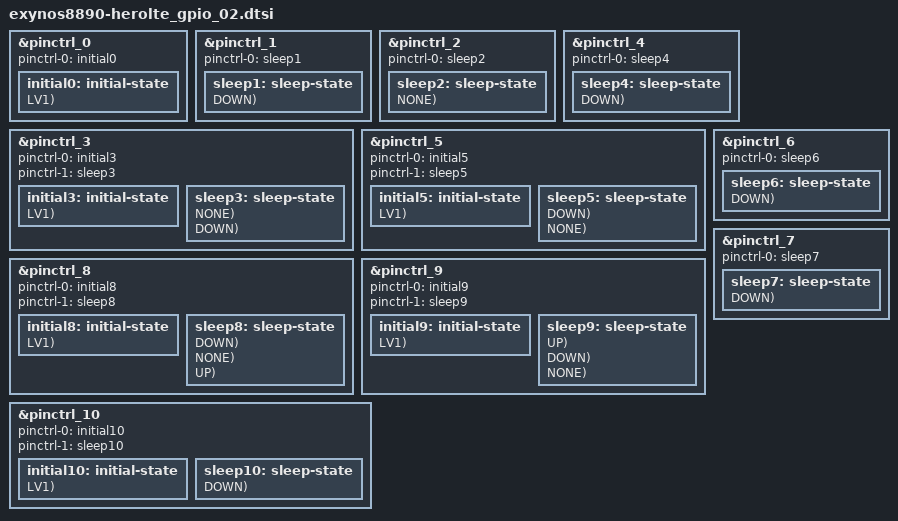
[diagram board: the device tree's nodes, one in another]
/*
 * Copyright (c) 2015 Samsung Electronics Co., Ltd.
 *		http://www.samsung.com
 *
 * This program is free software; you can redistribute it and/or modify
 * it under the terms of the GNU General Public License version 2 as
 * published by the Free Software Foundation.
*/

// Support LUCKY LTE HW REV0.7 (b1011)

#include "exynos_gpio_config_macros.dtsi"

// gpa: pinctrl_0
&pinctrl_0 {
	pinctrl-names = "default";
	pinctrl-0 = <&initial0>;
	initial0: initial-state {
		PIN_IN(gpa3-7, NONE, LV1);	/* 2ndCG_nIRQ */
	};
};

// gph0: do not add init setting for NC pins!!!
&pinctrl_1 {
	pinctrl-names = "sleep";
	pinctrl-0 = <&sleep1>;
	sleep1: sleep-state {
		PIN_SLP(gph0-0, INPUT, DOWN);	/* MM_I2S_CLK */
		PIN_SLP(gph0-1, INPUT, DOWN);	/* NC */
		PIN_SLP(gph0-2, INPUT, DOWN);	/* MM_I2S_SYNC */
		PIN_SLP(gph0-3, INPUT, DOWN);	/* MM_I2S_D_IN */
		PIN_SLP(gph0-4, INPUT, DOWN);	/* MM_I2S_D_OUT */
		PIN_SLP(gph0-5, INPUT, DOWN);	/* NC */
		PIN_SLP(gph0-6, INPUT, DOWN);	/* NC */
	};
};

// etc0
&pinctrl_2 {
	pinctrl-names = "sleep";
	pinctrl-0 = <&sleep2>;
	sleep2: sleep-state {
		PIN_SLP(etc0-0, PREV, NONE);	/* PMIC_SDA_1P8 */
		PIN_SLP(etc0-1, PREV, NONE);	/* PMIC_SCL_1P8 */
	};
};

// gpf3
&pinctrl_3 {
	pinctrl-names = "default","sleep";
	pinctrl-0 = <&initial3>;
	pinctrl-1 = <&sleep3>;
	initial3: initial-state {
		PIN_IN(gpf3-4, DOWN, LV1);	/* NC */
	};
	sleep3: sleep-state {
		PIN_SLP(gpf3-0, OUT0, NONE);	/* BTP_SPI_CLK */
		PIN_SLP(gpf3-1, OUT0, NONE);	/* BTP_SPI_CS_N */
		PIN_SLP(gpf3-2, INPUT, DOWN);	/* BTP_SPI_MISO */
		PIN_SLP(gpf3-3, OUT0, NONE);	/* BTP_SPI_MOSI */
		PIN_SLP(gpf3-4, INPUT, DOWN);	/* NC */
	};
};


// gpf2
&pinctrl_4 {
	pinctrl-names = "sleep";
	pinctrl-0 = <&sleep4>;
	sleep4: sleep-state {
		PIN_SLP(gpf2-0, INPUT, DOWN);	/* ESE_SPI_CLK */
		PIN_SLP(gpf2-1, INPUT, DOWN);	/* ESE_SPI_CS_N */
		PIN_SLP(gpf2-2, INPUT, DOWN);	/* ESE_SPI_MISO */
		PIN_SLP(gpf2-3, INPUT, DOWN);	/* ESE_SPI_MOSI */
	};
};

// gpi1, gpi2
&pinctrl_5 {
	pinctrl-names = "default","sleep";
	pinctrl-0 = <&initial5>;
	pinctrl-1 = <&sleep5>;
	initial5: initial-state {
		PIN_IN(gpi1-1, DOWN, LV1);	/* NC */

		PIN_IN(gpi2-5, DOWN, LV1);/* FG_ERR */
	};
	sleep5: sleep-state {
		PIN_SLP(gpi1-0, PREV, DOWN);	/* MST_PWR_EN */
		PIN_SLP(gpi1-1, INPUT, DOWN);	/* NC */
		PIN_SLP(gpi1-2, PREV, NONE);	/* WPC_EN */
		PIN_SLP(gpi1-3, PREV, NONE);	/* BTP_RST_N */

		PIN_SLP(gpi2-0, PREV, NONE);	/* DISP_RST_N */
		PIN_SLP(gpi2-1, INPUT, DOWN);	/* DISP_DET */
		PIN_SLP(gpi2-2, INPUT, DOWN);	/* DS_DET */
		PIN_SLP(gpi2-3, PREV, NONE);	/* BT_WAKE */
		PIN_SLP(gpi2-4, INPUT, DOWN);	/* IFC_SENSE_INT_AP */
		PIN_SLP(gpi2-5, INPUT, DOWN);	/* FG_ERR */
		PIN_SLP(gpi2-6, INPUT, NONE);	/* SUB_PMIC_IRQ_N */
		PIN_SLP(gpi2-7, PREV, NONE);	/* NFC_EN */
	};
};

// gpj0
&pinctrl_6 {
	pinctrl-names = "sleep";
	pinctrl-0 = <&sleep6>;
	sleep6: sleep-state {
		PIN_SLP(gpj0-2, INPUT, DOWN);	/* NC */
	};
};

// gpf0
&pinctrl_7 {
	pinctrl-names = "sleep";
	pinctrl-0= <&sleep7>;
	sleep7: sleep-state {
		PIN_SLP(gpf0-0, PREV, DOWN);	/* MST_EN */
		PIN_SLP(gpf0-1, PREV, DOWN);	/* MST_DATA_A */
		PIN_SLP(gpf0-2, INPUT, DOWN);	/* MST_DATA_B (not use yet) */
	};
};

// gpi0, gpd0~gpd3, gpb0~gpb2, gpc0~gpc3, gpk0, etc1
&pinctrl_8 {
	pinctrl-names = "default","sleep";
	pinctrl-0 = <&initial8>;
	pinctrl-1 = <&sleep8>;
	initial8: initial-state {
		PIN_IN(gpi0-0, DOWN, LV1);	/* NC */
		PIN_IN(gpi0-2, DOWN, LV1);	/* NC */
		PIN_IN(gpi0-3, DOWN, LV1);	/* NC */

		PIN_IN(gpd0-7, DOWN, LV1);	/* NC */

		PIN_IN(gpb0-2, DOWN, LV1);	/* NC */

		PIN_IN(gpb1-0, DOWN, LV1);	/* NC */

		PIN_IN(gpk0-3, DOWN, LV1);	/* NC */
	};
	sleep8: sleep-state {
		PIN_SLP(gpi0-0, INPUT, DOWN);	/* NC */
		PIN_SLP(gpi0-1, INPUT, DOWN);	/* BUCK11_EN */
		PIN_SLP(gpi0-2, INPUT, DOWN);	/* NC */
		PIN_SLP(gpi0-3, INPUT, DOWN);	/* NC */
		PIN_SLP(gpi0-4, PREV, NONE);	/* UFS_RST_N */
		PIN_SLP(gpi0-5, PREV, NONE);	/* UFS_REFCLK */

		PIN_SLP(gpd0-0, INPUT, UP);	/* 2MIC_UART_RXD */
		PIN_SLP(gpd0-1, PREV, NONE);	/* 2MIC_URAT_TXD */
		PIN_SLP(gpd0-2, PREV, NONE);	/* 2MIC_RST */
		PIN_SLP(gpd0-3, INPUT, DOWN);	/* 2MIC_INT */
		PIN_SLP(gpd0-4, PREV, NONE);	/* DISP_EN_1P6 */
		PIN_SLP(gpd0-5, OUT0, NONE);	/* VIB_PWN */
		PIN_SLP(gpd0-6, OUT1, NONE);    /* PMIC_WRST_IN */
		PIN_SLP(gpd0-7, INPUT, DOWN);	/* NC */

		PIN_SLP(gpd1-0, INPUT, NONE);	/* SPK_AMP_SDA_1P8 */
		PIN_SLP(gpd1-1, INPUT, NONE);	/* SPK_AMP_SCL_1P8 */
		PIN_SLP(gpd1-2, INPUT, NONE);	/* IF_PMIC_SDA_1P8 */
		PIN_SLP(gpd1-3, INPUT, NONE);	/* IF_PMIC_SCL_1P8 */
		PIN_SLP(gpd1-4, INPUT, NONE);	/* SUB_PMIC_SDA_1P8 */
		PIN_SLP(gpd1-5, INPUT, NONE);	/* SUB_PMIC_SCL_1P8 */

		PIN_SLP(gpd2-0, INPUT, NONE);	/* DISP_SDA_1P8 */
		PIN_SLP(gpd2-1, INPUT, NONE);	/* DISP_SCL_1P8 */
		PIN_SLP(gpd2-2, INPUT, NONE);	/* VTCAM_EEP_SDA_1P8 */
		PIN_SLP(gpd2-3, INPUT, NONE);	/* VTCAM_EEP_SCL_1P8 */

		PIN_SLP(gpd3-0, INPUT, NONE);	/* I2C4_SDA_1P8 */
		PIN_SLP(gpd3-1, INPUT, NONE);	/* I2C4_SCL_1P8 */
		PIN_SLP(gpd3-2, INPUT, NONE);	/* HRM_SDA_1P8 */
		PIN_SLP(gpd3-3, INPUT, NONE);	/* HRM_SCL_1P8 */

		PIN_SLP(gpb0-0, INPUT, DOWN);	/* DISP_TE */
		PIN_SLP(gpb0-1, INPUT, DOWN);	/* DISP_TE */
		PIN_SLP(gpb0-2, INPUT, DOWN);	/* NC */

		PIN_SLP(gpb1-0, INPUT, DOWN);	/* NC */
		PIN_SLP(gpb1-1, PREV, NONE);	/* GPS_HUB_EN */

		PIN_SLP(gpb2-0, PREV, NONE);	/* G3D_BUCK_DVS */
		PIN_SLP(gpb2-1, INPUT, NONE);	/* SMPL_WARN_AP */

		PIN_SLP(gpc0-0, INPUT, DOWN);	/* COMP_PAF_INT */
		PIN_SLP(gpc0-1, INPUT, DOWN);	/* TP */
		PIN_SLP(gpc0-2, INPUT, DOWN);	/* CAM_FLASH_EN */
		PIN_SLP(gpc0-3, INPUT, DOWN);	/* CAM_TORCH_EN */
		PIN_SLP(gpc0-4, INPUT, DOWN);	/* VTCAM_RST_N */

		PIN_SLP(gpc1-0, INPUT, DOWN);	/* CAM_RST_N */
		PIN_SLP(gpc1-1, INPUT, DOWN);	/* VTCAM_STBY */
		PIN_SLP(gpc1-2, INPUT, DOWN);	/* COMP_RST_N */
		PIN_SLP(gpc1-3, INPUT, DOWN);	/* CAM_SENSOR_DET */
		PIN_SLP(gpc1-4, INPUT, DOWN);	/* TP */

		PIN_SLP(gpc2-0, INPUT, NONE);	/* CAM_SDA */
		PIN_SLP(gpc2-1, INPUT, NONE);	/* CAM_SCL */
		PIN_SLP(gpc2-2, INPUT, DOWN);	/* VTCAM_SDA */
		PIN_SLP(gpc2-3, INPUT, DOWN);	/* VTCAM_SCL */
		PIN_SLP(gpc2-4, INPUT, NONE);	/* OIS_AF_SDA */
		PIN_SLP(gpc2-5, INPUT, NONE);	/* OIS_AF_SCL */

		PIN_SLP(gpc3-0, INPUT, DOWN);	/* FROM_SPI_CLK */
		PIN_SLP(gpc3-1, PREV, NONE);	/* FROM_SPI_SS_N */
		PIN_SLP(gpc3-2, INPUT, DOWN);	/* FROM_SPI_MISO */
		PIN_SLP(gpc3-3, INPUT, DOWN);	/* FROM_SPI_MOSI */
		PIN_SLP(gpc3-4, INPUT, DOWN);	/* COMP_SPI_CLK */
		PIN_SLP(gpc3-5, INPUT, DOWN);	/* COMP_SPI_SS_N */
		PIN_SLP(gpc3-6, INPUT, DOWN);	/* COMP_SPI_MISO */
		PIN_SLP(gpc3-7, INPUT, DOWN);	/* COMP_SPI_MOSI */

		PIN_SLP(gpk0-0, INPUT, DOWN);	/* CAM_MCLK */
		PIN_SLP(gpk0-1, INPUT, DOWN);	/* COMP_MCLK */
		PIN_SLP(gpk0-2, INPUT, DOWN);	/* VTCAM_MCLK */
		PIN_SLP(gpk0-3, INPUT, DOWN);	/* NC */

		PIN_SLP(etc1-0, INPUT, DOWN);	/* JTAG_TRST_N */
		PIN_SLP(etc1-1, INPUT, DOWN);	/* JTAG_TMS */
		PIN_SLP(etc1-2, INPUT, DOWN);	/* JTAG_TCK */
		PIN_SLP(etc1-3, INPUT, DOWN);	/* JTAG_TDI */
		PIN_SLP(etc1-4, INPUT, DOWN);	/* JTAG_TDO */
		PIN_SLP(etc1-5, INPUT, DOWN);	/* AP_JTAG_DBGSEL */
		PIN_SLP(etc1-6, INPUT, DOWN);	/* XJDBGSRCSEL */
	};
};

// gpe0~gpe7, gpj1~gpj2, gpg0
&pinctrl_9 {
	pinctrl-names = "default","sleep";
	pinctrl-0 = <&initial9>;
	pinctrl-1 = <&sleep9>;
	initial9: initial-state {
		PIN_IN(gpe0-6, DOWN, LV1);	/* NC */
		PIN_IN(gpe0-7, DOWN, LV1);	/* NC */

		PIN_IN(gpe1-2, DOWN, LV1);	/* NC */
		PIN_IN(gpe1-3, DOWN, LV1);	/* NC */
		PIN_IN(gpe1-4, DOWN, LV1);	/* NC */
		PIN_IN(gpe1-5, DOWN, LV1);	/* NC */
		PIN_IN(gpe1-6, DOWN, LV1);	/* NC */
		PIN_IN(gpe1-7, DOWN, LV1);	/* NC */

		PIN_IN(gpe3-4, DOWN, LV1);	/* NC */
		PIN_IN(gpe3-5, DOWN, LV1);	/* NC */
		PIN_IN(gpe3-6, DOWN, LV1);	/* NC */
		PIN_IN(gpe3-7, DOWN, LV1);	/* NC */

		PIN_IN(gpe4-0, DOWN, LV1);	/* NC */
		PIN_IN(gpe4-1, DOWN, LV1);	/* NC */
		PIN_IN(gpe4-2, DOWN, LV1);	/* NC */
		PIN_IN(gpe4-3, DOWN, LV1);	/* NC */
		PIN_IN(gpe4-4, NONE, LV1);	/* HW_REV(0) */
		PIN_IN(gpe4-5, NONE, LV1);	/* HW_REV(1) */
		PIN_IN(gpe4-6, NONE, LV1);	/* HW_REV(2) */
		PIN_IN(gpe4-7, NONE, LV1);	/* HW_REV(3) */

		PIN_IN(gpe6-7, DOWN, LV1);	/* NC */

		/*PIN_IN(gpe7-3, DOWN, LV1);*/	/* NC */

		PIN_IN(gpj1-1, DOWN, LV1);	/* NC */
		PIN_IN(gpj1-4, DOWN, LV1);	/* NC */
		PIN_IN(gpj1-5, DOWN, LV1);	/* NC */
		PIN_IN(gpj1-6, DOWN, LV1);	/* NC */

		PIN_IN(gpj2-0, DOWN, LV1);	/* NC */
		PIN_IN(gpj2-1, DOWN, LV1);	/* NC */

		PIN_IN(gpg0-1, DOWN, LV1);	/* NC */
	};
	sleep9: sleep-state {
		PIN_SLP(gpe0-0, INPUT, UP);	/* BT_UART_RXD */
		PIN_SLP(gpe0-1, OUT1, UP);	/* BT_UART_TXD */
		PIN_SLP(gpe0-2, INPUT, UP);	/* BT_UART_CTS */
		PIN_SLP(gpe0-3, OUT1, UP);	/* BT_UART_RTS */
		PIN_SLP(gpe0-4, INPUT, DOWN);	/* OLED_ID */
		PIN_SLP(gpe0-5, INPUT, DOWN);	/* T_Flash_VDD_En */
		PIN_SLP(gpe0-6, INPUT, DOWN);	/* NC */
		PIN_SLP(gpe0-7, INPUT, DOWN);	/* NC */

		PIN_SLP(gpe1-0, INPUT, DOWN);	/* AP_UART_RXD */
		PIN_SLP(gpe1-1, INPUT, DOWN);	/* AP_UART_TXD */
		PIN_SLP(gpe1-2, INPUT, DOWN);	/* NC */
		PIN_SLP(gpe1-3, INPUT, DOWN);	/* NC */
		PIN_SLP(gpe1-4, INPUT, DOWN);	/* NC */
		PIN_SLP(gpe1-5, INPUT, DOWN);	/* NC */
		PIN_SLP(gpe1-6, INPUT, DOWN);	/* NC */
		PIN_SLP(gpe1-7, INPUT, DOWN);	/* NC */

		PIN_SLP(gpe2-0, INPUT, DOWN);	/* CODEC_SPI_SCK */
		PIN_SLP(gpe2-1, INPUT, DOWN);	/* CODEC_SPI_SS_N */
		PIN_SLP(gpe2-2, INPUT, DOWN);	/* CODEC_SPI_MISO */
		PIN_SLP(gpe2-3, INPUT, DOWN);	/* CODEC_SPI_MOSI */
		PIN_SLP(gpe2-4, OUT1, UP);	/* SHUB_SPI_SCK */
		PIN_SLP(gpe2-5, OUT1, UP);	/* SHUB_SPI_SS_N */
		PIN_SLP(gpe2-6, INPUT, DOWN);	/* SHUB_SPI_MISO */
		PIN_SLP(gpe2-7, OUT1, UP);	/* SHUB_SPI_MOSI */

		PIN_SLP(gpe3-0, PREV, NONE);	/* BTP_LDO_EN1 */
		PIN_SLP(gpe3-1, PREV, NONE);	/* BTP_LDO_EN2 */
		PIN_SLP(gpe3-2, PREV, DOWN);	/* BTP_ID */
		PIN_SLP(gpe3-3, INPUT, DOWN);	/* VTCAM_ID */
		PIN_SLP(gpe3-4, INPUT, DOWN);	/* NC */
		PIN_SLP(gpe3-5, INPUT, DOWN);	/* NC */
		PIN_SLP(gpe3-6, INPUT, DOWN);	/* NC */
		PIN_SLP(gpe3-7, INPUT, DOWN);	/* NC */

		PIN_SLP(gpe4-0, INPUT, DOWN);	/* UB_SPI_CLK */
		PIN_SLP(gpe4-1, INPUT, DOWN);	/* UB_SPI_CS_N */
		PIN_SLP(gpe4-2, INPUT, DOWN);	/* UB_SPI_MISO */
		PIN_SLP(gpe4-3, INPUT, DOWN);	/* UB_SPI_MOSI */
		PIN_SLP(gpe4-4, INPUT, NONE);	/* HW_REV(0) */
		PIN_SLP(gpe4-5, INPUT, NONE);	/* HW_REV(1) */
		PIN_SLP(gpe4-6, INPUT, NONE);	/* HW_REV(2) */
		PIN_SLP(gpe4-7, INPUT, NONE);	/* HW_REV(3) */

		PIN_SLP(gpe5-0, INPUT, NONE);	/* I2C2_SDA_1P8(NC) */
		PIN_SLP(gpe5-1, INPUT, NONE);	/* I2C2_SCL_1P8(NC) */
		PIN_SLP(gpe5-2, INPUT, NONE);	/* TOUCH_SDA_1P8 */
		PIN_SLP(gpe5-3, INPUT, NONE);	/* TOUCH_SCL_1P8 */
		PIN_SLP(gpe5-4, INPUT, NONE);	/* MEM_SDA_1P8 */
		PIN_SLP(gpe5-5, INPUT, NONE);	/* MEM_SCL_1P8 */
		PIN_SLP(gpe5-6, INPUT, NONE);	/* WPC_SDA_1P8 */
		PIN_SLP(gpe5-7, INPUT, NONE);	/* WPC_SCL_1P8 */

		PIN_SLP(gpe6-0, INPUT, NONE);	/* 2MIC_SDA_1P8 */
		PIN_SLP(gpe6-1, INPUT, NONE);	/* 2MIC_SCL_1P8 */
		PIN_SLP(gpe6-2, INPUT, NONE);	/* HD_HAPTIC_SDA_1P8*/
		PIN_SLP(gpe6-3, INPUT, NONE);	/* HD_HAPTIC_SCL_1P8 */
		PIN_SLP(gpe6-4, OUT0, DOWN);	/* AP_MCU_INT_1P8 */
		PIN_SLP(gpe6-5, PREV, NONE);	/* CODEC_RST_N */
		PIN_SLP(gpe6-6, OUT0, NONE);	/* NFC_WPT_MODE */
		PIN_SLP(gpe6-7, INPUT, NONE);	/* USB_3.0_CON_SEL */

		PIN_SLP(gpe7-0, OUT0, DOWN);	/* NFC_FIRM */
		PIN_SLP(gpe7-1, INPUT, DOWN);	/* TSP_ID */
		PIN_SLP(gpe7-2, INPUT, DOWN);	/* TSP_ID2 */
		/*PIN_SLP(gpe7-3, INPUT, DOWN);*/	/* NC */

		PIN_SLP(gpj1-0, INPUT, NONE);	/* PCIE_CLK_REQ_L */
		PIN_SLP(gpj1-1, INPUT, DOWN);	/* NC */
		PIN_SLP(gpj1-2, PREV, NONE);	/* PCIE_RST_L */
		PIN_SLP(gpj1-3, PREV, NONE);	/* WLAN_EN */
		PIN_SLP(gpj1-4, INPUT, DOWN);	/* NC */
		PIN_SLP(gpj1-5, INPUT, DOWN);	/* NC */
		PIN_SLP(gpj1-6, INPUT, DOWN);	/* NC */
		PIN_SLP(gpj1-7, PREV, NONE);	/* BT_EN */

		PIN_SLP(gpj2-0, INPUT, DOWN);	/* NC */
		PIN_SLP(gpj2-1, INPUT, DOWN);	/* NC */

		PIN_SLP(gpg0-0, OUT0, NONE);	/* XBOOTLDO0 */
		PIN_SLP(gpg0-1, INPUT, DOWN);	/* NC */
		PIN_SLP(gpg0-2, INPUT, DOWN);	/* MCU_AP_INT_1P8 */
	};
};

// gpf1
&pinctrl_10 {
	pinctrl-names = "default","sleep";
	pinctrl-0 = <&initial10>;
	pinctrl-1 = <&sleep10>;
	initial10: initial-state {
		PIN_IN(gpf1-2, DOWN, LV1);	/* NC */
	};
	sleep10: sleep-state {
		PIN_SLP(gpf1-0, INPUT, DOWN);	/* TSP_SDA_1.8V */
		PIN_SLP(gpf1-1, INPUT, DOWN);	/* TSP_SCL_1.8V */
		PIN_SLP(gpf1-2, INPUT, DOWN);	/* NC */
	};
};
